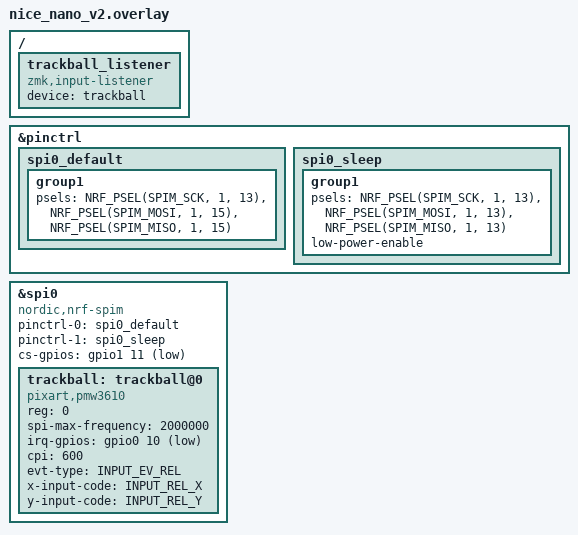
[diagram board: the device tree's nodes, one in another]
&pinctrl {
    spi0_default: spi0_default {
        group1 {
            psels = <NRF_PSEL(SPIM_SCK, 1, 13)>,
                <NRF_PSEL(SPIM_MOSI, 1, 15)>,
                <NRF_PSEL(SPIM_MISO, 1, 15)>;
        };
    };

    spi0_sleep: spi0_sleep {
        group1 {
            psels = <NRF_PSEL(SPIM_SCK, 1, 13)>,
                <NRF_PSEL(SPIM_MOSI, 1, 13)>,
                <NRF_PSEL(SPIM_MISO, 1, 13)>;
            low-power-enable;
        };
    };
};

&spi0 {
    status = "okay";
    compatible = "nordic,nrf-spim";
    pinctrl-0 = <&spi0_default>;
    pinctrl-1 = <&spi0_sleep>;
    pinctrl-names = "default", "sleep";
    cs-gpios = <&gpio1 11 GPIO_ACTIVE_LOW>;

    trackball: trackball@0 {
        status = "okay";
        compatible = "pixart,pmw3610";
        reg = <0>;
        spi-max-frequency = <2000000>;
        irq-gpios = <&gpio0 10 (GPIO_ACTIVE_LOW | GPIO_PULL_UP)>;
        cpi = <600>;
        evt-type = <INPUT_EV_REL>;
        x-input-code = <INPUT_REL_X>;
        y-input-code = <INPUT_REL_Y>;
    };
};

/ {
  trackball_listener {
    compatible = "zmk,input-listener";
    device = <&trackball>;
  };
};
